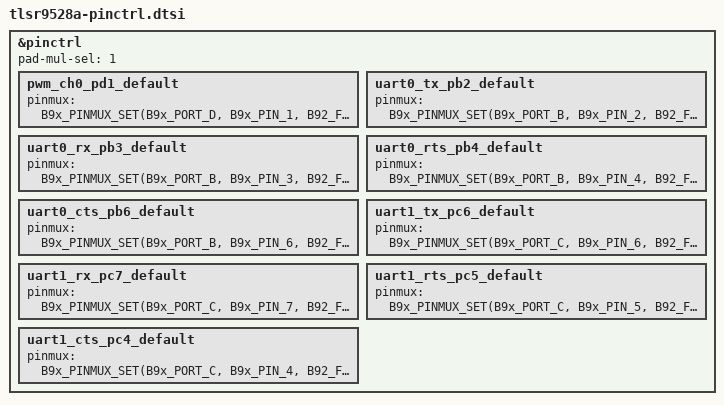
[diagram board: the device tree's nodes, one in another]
/*
 * Copyright (c) 2023 Telink Semiconductor
 *
 * SPDX-License-Identifier: Apache-2.0
 */

#include <zephyr/dt-bindings/pinctrl/b92-pinctrl.h>

&pinctrl {
	/* Set pad-mul-sel register value.
	 * Note: Pins functions below (pinmux = <...>) depend on this value.
	 */
	pad-mul-sel = <1>;

	pwm_ch0_pd1_default: pwm_ch0_pd1_default {
		pinmux = <B9x_PINMUX_SET(B9x_PORT_D, B9x_PIN_1, B92_FUNC_PWM0)>;
	};

	/* UART0: TX(PB2), RX(PB3), RTS(PB4), CTS(PB6) */

	uart0_tx_pb2_default: uart0_tx_pb2_default {
		pinmux = <B9x_PINMUX_SET(B9x_PORT_B, B9x_PIN_2, B92_FUNC_UART0_TX)>;
	};
	uart0_rx_pb3_default: uart0_rx_pb3_default {
		pinmux = <B9x_PINMUX_SET(B9x_PORT_B, B9x_PIN_3, B92_FUNC_UART0_RTX_IO)>;
	};
	uart0_rts_pb4_default: uart0_rts_pb4_default {
		pinmux = <B9x_PINMUX_SET(B9x_PORT_B, B9x_PIN_4, B92_FUNC_UART0_RTS)>;
	};
	uart0_cts_pb6_default: uart0_cts_pb6_default {
		pinmux = <B9x_PINMUX_SET(B9x_PORT_B, B9x_PIN_6, B92_FUNC_UART0_CTS_I)>;
	};

	/* UART1: TX(PC6), RX(PC7), RTS(PC5), CTS(PC4) */

	uart1_tx_pc6_default: uart1_tx_pc6_default {
		pinmux = <B9x_PINMUX_SET(B9x_PORT_C, B9x_PIN_6, B92_FUNC_UART1_TX)>;
	};
	uart1_rx_pc7_default: uart1_rx_pc7_default {
		pinmux = <B9x_PINMUX_SET(B9x_PORT_C, B9x_PIN_7, B92_FUNC_UART1_RTX_IO)>;
	};
	uart1_rts_pc5_default: uart1_rts_pc5_default {
		pinmux = <B9x_PINMUX_SET(B9x_PORT_C, B9x_PIN_5, B92_FUNC_UART1_RTS)>;
	};
	uart1_cts_pc4_default: uart1_cts_pc4_default {
		pinmux = <B9x_PINMUX_SET(B9x_PORT_C, B9x_PIN_4, B92_FUNC_UART1_CTS_I)>;
	};

};
